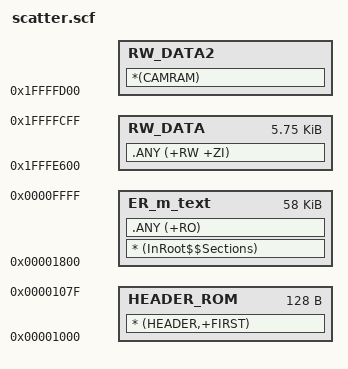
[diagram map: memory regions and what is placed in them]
#! armcc -E
#define m_header_start                 0x00001000
#define m_header_size                  0x00000080

#define m_interrupts_start             0x00001400
#define m_interrupts_size              0x00000400

#define m_text_start                   (m_interrupts_start + m_interrupts_size)
#define m_text_size                    (0x10000 - m_text_start)

; 8KB - 768 bytes for camera - 1.5KB for stack
#define m_data_start                   0x1FFFE600
#define m_data_size                    0x00001700   

; 8KB + 768 bytes
#define m_data_2_start                 0x1FFFFD00   
#define m_data_2_size                  0x00002300

LR_m_text m_text_start m_text_size {   ; load region size_region
  ER_m_text m_text_start m_text_size { ; load address = execution address
    * (InRoot$$Sections)
    .ANY (+RO)
  }
  
  RW_DATA m_data_start m_data_size { ; RW data
    .ANY (+RW +ZI)
  }
  
  RW_DATA2 m_data_2_start { ; RW data
    *(CAMRAM)
  }
}

LR_m_header m_header_start m_header_size {
  HEADER_ROM m_header_start m_header_size {
    * (HEADER,+FIRST)
  }
}
